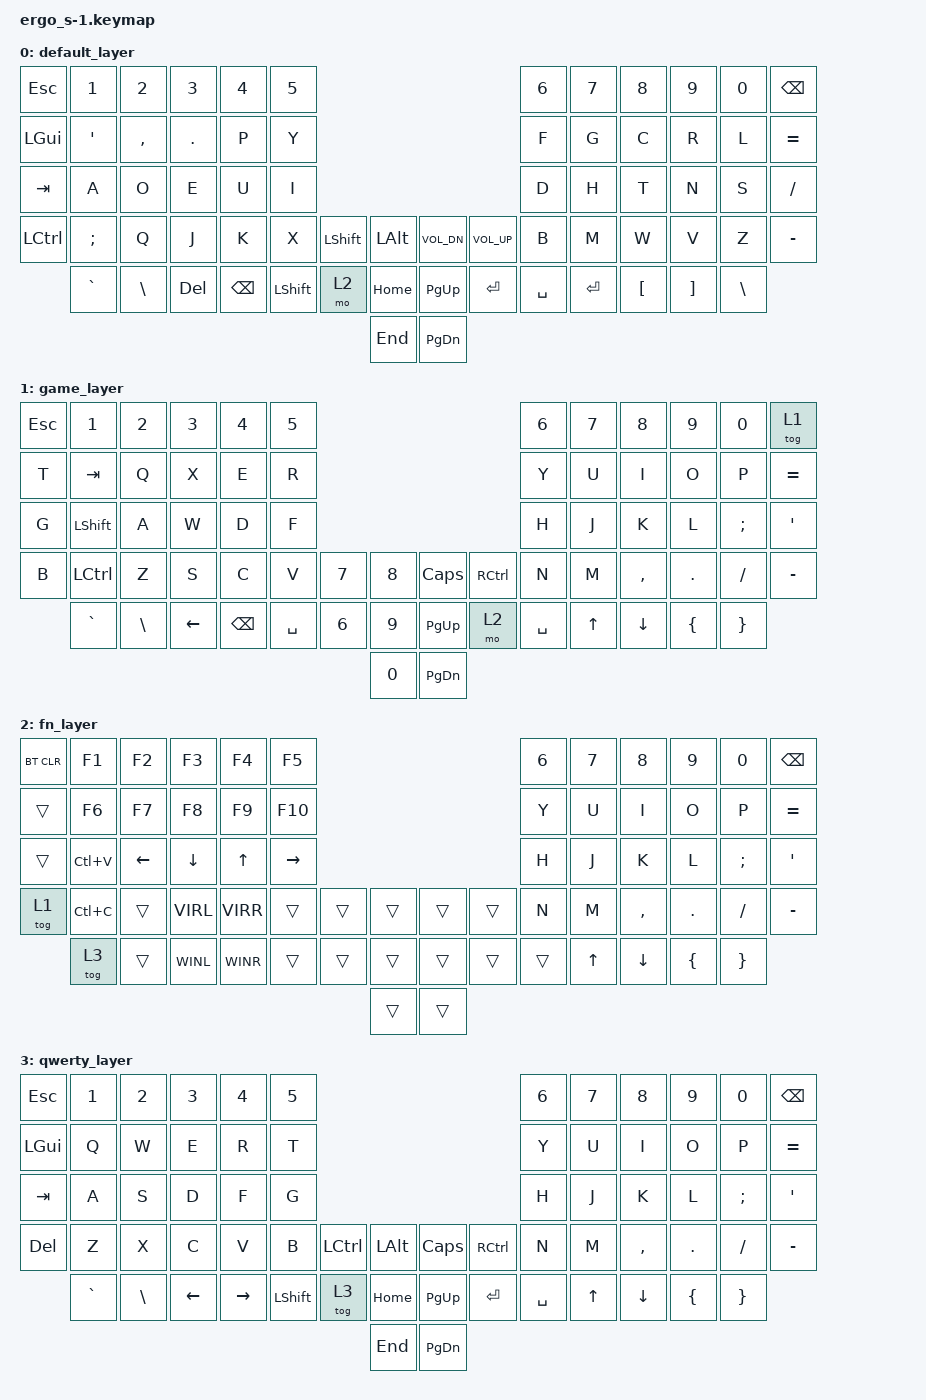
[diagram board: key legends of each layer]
/*
 * Copyright (c) 2020 The ZMK Contributors
 *
 * SPDX-License-Identifier: MIT
 */

 #include <behaviors.dtsi>
 #include <dt-bindings/zmk/keys.h>
 #include <dt-bindings/zmk/bt.h>
 #include <dt-bindings/zmk/outputs.h>
 #define VIRL LC(LG(LEFT))
 #define VIRR LC(LG(RIGHT))
 #define WINL LG(LEFT)
 #define WINR LG(RIGHT)

 #define DEFAULT 0
 #define FN  2
 #define GAME 1
 #define QWERTY 3

// | ESC  |  1   |  2   |  3   |  4   |  5   |                                                   |  6   |  7   |  8   |  9   |  0   | BSPC |
// | WIN  |  Q   |  W   |  E   |  R   |  T   |                                                   |  Y   |  U   |  I   |  O   |  P   | EQL  |
// | TAB  |  A   |  S   |  D   |  F   |  G   |                                                   |  H   |  J   |  K   |  L   | SCLN | QUOT |
// | DEL  |  Z   |  X   |  C   |  V   |  B   |      | CTL  | ALT  |         | CAPS | CTL  |      |  N   |  M   | COMM | DOT  | SLSH | MINS |
//        | GRV  | BSLS | LEFT | RGHT |      | SHFT |  FN  | HOME |         | PGUP | ENT  | SPC  |      |  UP  |  DN  | LBRC | RBRC |
//                                                         | END  |         | PGDN |

/ {
       keymap {
              compatible = "zmk,keymap";
 
              default_layer {
// ---------------------------------------------------------------------------------------------------------------------------------
// | ESC  |  1   |  2   |  3   |  4   |  5   |                                                   |  6   |  7   |  8   |  9   |  0   | BSPC |
// | WIN  |  Q   |  W   |  E   |  R   |  T   |                                                   |  Y   |  U   |  I   |  O   |  P   | EQL  |
// | TAB  |  A   |  S   |  D   |  F   |  G   |                                                   |  H   |  J   |  K   |  L   | SCLN | QUOT |
// | LCTL |  Z   |  X   |  C   |  V   |  B   |      | CTL  | ALT  |         | CAPS | CTL  |      |  N   |  M   | COMM | DOT  | SLSH | MINS |
//        | GRV  | BSLS | LEFT | RGHT |      | SHFT |  FN  | HOME |         | PGUP | ENT  | SPC  |      |  UP  |  DN  | LBRC | RBRC |
//                                                         | END  |         | PGDN |
                     bindings = <
       &kp ESC    &kp N1    &kp N2   &kp N3   &kp N4    &kp N5                                                                    &kp N6    &kp N7    &kp N8    &kp N9     &kp N0    &kp BSPC
       &kp LGUI   &kp SQT   &kp COMMA&kp DOT  &kp P     &kp Y                                                                     &kp F     &kp G     &kp C     &kp R      &kp L     &kp EQUAL
       &kp TAB    &kp A     &kp O    &kp E    &kp U     &kp I                                                                     &kp D     &kp H     &kp T     &kp N      &kp S     &kp SLASH
       &kp LCTRL  &kp SEMI  &kp Q    &kp J    &kp K     &kp X            &kp LSHFT &kp LALT      &kp C_VOL_DN  &kp C_VOL_UP       &kp B     &kp M     &kp W     &kp V      &kp Z     &kp MINUS
                  &kp GRAVE &kp BSLH &kp DEL  &kp BSPC         &kp LSHFT &mo 2     &kp HOME      &kp PG_UP &kp ENTER &kp SPACE    &kp ENTER &kp LBKT  &kp RBKT  &kp BSLH
                                                                                   &kp END       &kp PG_DN 
                     >;
              };
              game_layer {
// ---------------------------------------------------------------------------------------------------------------------------------
// | ESC  |  1   |  2   |  3   |  4   |  5   |                                                   |  6   |  7   |  8   |  9   |  0   | BSPC |
// | WIN  |  Q   |  W   |  E   |  R   |  T   |                                                   |  Y   |  U   |  I   |  O   |  P   | EQL  |
// | TAB  |  A   |  S   |  D   |  F   |  G   |                                                   |  H   |  J   |  K   |  L   | SCLN | QUOT |
// | LCTL |  Z   |  X   |  C   |  V   |  B   |      | CTL  | ALT  |         | CAPS | CTL  |      |  N   |  M   | COMM | DOT  | SLSH | MINS |
//        | GRV  | BSLS | LEFT | RGHT |      | SHFT |  FN  | HOME |         | PGUP | ENT  | SPC  |      |  UP  |  DN  | LBRC | RBRC |
//                                                         | END  |         | PGDN |
                     bindings = <
       &kp ESC    &kp N1    &kp N2  &kp N3   &kp N4   &kp N5                                                                   &kp N6    &kp N7    &kp N8    &kp N9     &kp N0    &tog 1
       &kp T      &kp TAB   &kp Q   &kp X    &kp E    &kp R                                                                    &kp Y     &kp U     &kp I     &kp O      &kp P     &kp EQUAL
       &kp G      &kp LSHFT &kp A   &kp W    &kp D    &kp F                                                                    &kp H     &kp J     &kp K     &kp L      &kp SEMI  &kp SQT
       &kp B      &kp LCTRL &kp Z   &kp S    &kp C    &kp V               &kp 7     &kp 8         &kp CAPS  &kp RCTRL          &kp N     &kp M     &kp COMMA &kp PERIOD &kp SLASH &kp MINUS
                  &kp GRAVE &kp BSLH &kp LEFT &kp BSPC          &kp SPACE &kp 6     &kp 9         &kp PG_UP &mo 2 &kp SPACE              &kp UP    &kp DOWN  &kp LBRC   &kp RBRC
                                                                                    &kp 0         &kp PG_DN 
                     >;
              };
              fn_layer {
// ---------------------------------------------------------------------------------------------------------------------------------
// |      |  F1  |  F2  |  F3  |  F4  |  F5  |                                                   |      | NMLK |  =   |  =   |  0   |      |
// |      |  F6  |  F7  |  F8  |  F9  |  F10 |                                                   |      |  7   |  8   |  9   |  *   |      |
// |      |      |      |      |      |      |                                                   |      |  4   |  5   |  6   |  +   |      |
// |      |      |      |      |      | PTSC |      |      |      |         |      |      |      |      |  1   |  2   |  3   | ENT  |      |
//        |      | INS  |      |      |      |      |  FN  |      |         |      |      |      |      |      |      |  .   | ENT  |
//                                                         |      |         |      |
                     bindings = <
       &bt BT_CLR &kp F1           &kp F2   &kp F3   &kp F4    &kp F5                                                                    &kp N6    &kp N7    &kp N8    &kp N9     &kp N0    &kp BSPC
       &trans     &kp F6           &kp F7   &kp F8   &kp F9    &kp F10                                                                   &kp Y     &kp U     &kp I     &kp O      &kp P     &kp EQUAL
       &trans     &kp LC(V)        &kp LEFT &kp DOWN &kp UP    &kp RIGHT                                                                 &kp H     &kp J     &kp K     &kp L      &kp SEMI  &kp SQT
       &tog 1     &kp LC(C)        &trans   &kp VIRL &kp VIRR  &trans              &trans    &trans        &trans    &trans              &kp N     &kp M     &kp COMMA &kp PERIOD &kp SLASH &kp MINUS
                  &tog 3           &trans   &kp WINL &kp WINR            &trans    &trans    &trans        &trans    &trans    &trans              &kp UP    &kp DOWN  &kp LBRC   &kp RBRC
                                                                                    &trans        &trans    
                     >;
              };
              qwerty_layer {
// ---------------------------------------------------------------------------------------------------------------------------------
// | ESC  |  1   |  2   |  3   |  4   |  5   |                                                   |  6   |  7   |  8   |  9   |  0   | BSPC |
// | WIN  |  Q   |  W   |  E   |  R   |  T   |                                                   |  Y   |  U   |  I   |  O   |  P   | EQL  |
// | TAB  |  A   |  S   |  D   |  F   |  G   |                                                   |  H   |  J   |  K   |  L   | SCLN | QUOT |
// | LCTL |  Z   |  X   |  C   |  V   |  B   |      | CTL  | ALT  |         | CAPS | CTL  |      |  N   |  M   | COMM | DOT  | SLSH | MINS |
//        | GRV  | BSLS | LEFT | RGHT |      | SHFT |  FN  | HOME |         | PGUP | ENT  | SPC  |      |  UP  |  DN  | LBRC | RBRC |
//                                                         | END  |         | PGDN |
                     bindings = <
       &kp ESC    &kp N1  &kp N2   &kp N3   &kp N4    &kp N5                                                                    &kp N6    &kp N7    &kp N8    &kp N9     &kp N0    &kp BSPC
       &kp LGUI   &kp Q   &kp W    &kp E    &kp R     &kp T                                                                     &kp Y     &kp U     &kp I     &kp O      &kp P     &kp EQUAL
       &kp TAB    &kp A   &kp S    &kp D    &kp F     &kp G                                                                     &kp H     &kp J     &kp K     &kp L      &kp SEMI  &kp SQT
       &kp DEL    &kp Z   &kp X    &kp C    &kp V     &kp B               &kp LCTRL &kp LALT      &kp CAPS  &kp RCTRL           &kp N     &kp M     &kp COMMA &kp PERIOD &kp SLASH &kp MINUS
                  &kp GRAVE &kp BSLH &kp LEFT &kp RIGHT         &kp LSHFT &tog 3    &kp HOME      &kp PG_UP &kp ENTER &kp SPACE           &kp UP    &kp DOWN  &kp LBRC   &kp RBRC
                                                                                    &kp END       &kp PG_DN 
                     >;
              };

//               fn_layer {
// // ---------------------------------------------------------------------------------------------------------------------------------
// // |      |  F1  |  F2  |  F3  |  F4  |  F5  |                                                   |      | NMLK |  =   |  =   |  0   |      |
// // |      |  F6  |  F7  |  F8  |  F9  |  F10 |                                                   |      |  7   |  8   |  9   |  *   |      |
// // |      |      |      |      |      |      |                                                   |      |  4   |  5   |  6   |  +   |      |
// // |      |      |      |      |      | PTSC |      |      |      |         |      |      |      |      |  1   |  2   |  3   | ENT  |      |
// //        |      | INS  |      |      |      |      |  FN  |      |         |      |      |      |      |      |      |  .   | ENT  |
// //                                                         |      |         |      |
//                      bindings = <
//        &bt BT_CLR &kp F1  &kp F2   &kp F3   &kp F4    &kp F5                                                                    &kp N6    &kp N7    &kp N8    &kp N9     &kp N0    &kp BSPC
//        &trans     &kp F6  &kp F7   &kp F8   &kp F9    &kp F10                                                                   &kp Y     &kp U     &kp I     &kp O      &kp P     &kp EQUAL
//        &trans     &trans  &trans   &trans   &trans    &trans                                                                    &kp H     &kp J     &kp K     &kp L      &kp SEMI  &kp SQT
//        &trans     &trans  &trans   &trans   &trans    &trans              &trans    &trans        &trans    &trans              &kp N     &kp M     &kp COMMA &kp PERIOD &kp SLASH &kp MINUS
//                   &trans  &trans   &trans   &trans              &trans    &trans    &trans        &trans    &trans    &trans              &kp UP    &kp DOWN  &kp LBRC   &kp RBRC
//                                                                                     &trans        &trans    
//                      >;
//               };
//               qwerty_layer {
// // ---------------------------------------------------------------------------------------------------------------------------------
// // | ESC  |  1   |  2   |  3   |  4   |  5   |                                                   |  6   |  7   |  8   |  9   |  0   | BSPC |
// // | WIN  |  Q   |  W   |  E   |  R   |  T   |                                                   |  Y   |  U   |  I   |  O   |  P   | EQL  |
// // | TAB  |  A   |  S   |  D   |  F   |  G   |                                                   |  H   |  J   |  K   |  L   | SCLN | QUOT |
// // | LCTL |  Z   |  X   |  C   |  V   |  B   |      | CTL  | ALT  |         | CAPS | CTL  |      |  N   |  M   | COMM | DOT  | SLSH | MINS |
// //        | GRV  | BSLS | LEFT | RGHT |      | SHFT |  FN  | HOME |         | PGUP | ENT  | SPC  |      |  UP  |  DN  | LBRC | RBRC |
// //                                                         | END  |         | PGDN |
//                      bindings = <
//        &kp ESC    &kp N1  &kp N2   &kp N3   &kp N4    &kp N5                                                                    &kp N6    &kp N7    &kp N8    &kp N9     &kp N0    &kp BSPC
//        &kp LGUI   &kp Q   &kp W    &kp E    &kp R     &kp T                                                                     &kp Y     &kp U     &kp I     &kp O      &kp P     &kp EQUAL
//        &kp TAB    &kp A   &kp S    &kp D    &kp F     &kp G                                                                     &kp H     &kp J     &kp K     &kp L      &kp SEMI  &kp SQT
//        &kp DEL    &kp Z   &kp X    &kp C    &kp V     &kp B               &kp LCTRL &kp LALT      &kp CAPS  &kp RCTRL           &kp N     &kp M     &kp COMMA &kp PERIOD &kp SLASH &kp MINUS
//                   &kp GRAVE &kp BSLH &kp LEFT &kp RIGHT         &kp LSHFT &mo 1     &kp HOME      &kp PG_UP &kp ENTER &kp SPACE           &kp UP    &kp DOWN  &kp LBRC   &kp RBRC
//                                                                                     &kp END       &kp PG_DN 
//                      >;
//               };
      };
};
